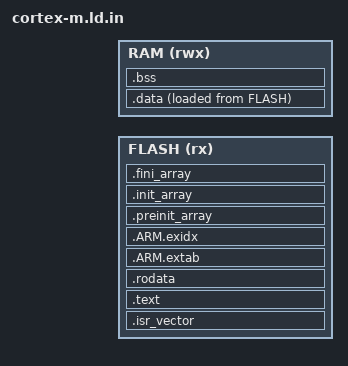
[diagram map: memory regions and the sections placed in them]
/*
 * VirtuLab CI — generic Cortex-M linker script.
 * @FLASH_ORIGIN@ etc. are filled in from the board definition.
 */
ENTRY(Reset_Handler)

MEMORY
{
    FLASH (rx)  : ORIGIN = @FLASH_ORIGIN@, LENGTH = @FLASH_SIZE@
    RAM   (rwx) : ORIGIN = @RAM_ORIGIN@, LENGTH = @RAM_SIZE@
}

_estack = ORIGIN(RAM) + LENGTH(RAM);
_min_stack_size = @MIN_STACK@;

SECTIONS
{
    .isr_vector :
    {
        . = ALIGN(4);
        KEEP(*(.isr_vector))
        KEEP(*(.vectors))
        . = ALIGN(4);
    } > FLASH

    .text :
    {
        *(.text*)
        *(.glue_7)
        *(.glue_7t)
        *(.eh_frame)
        KEEP(*(.init))
        KEEP(*(.fini))
        . = ALIGN(4);
    } > FLASH

    .rodata :
    {
        . = ALIGN(4);
        *(.rodata*)
        . = ALIGN(4);
    } > FLASH

    .ARM.extab : { *(.ARM.extab* .gnu.linkonce.armextab.*) } > FLASH
    .ARM.exidx :
    {
        __exidx_start = .;
        *(.ARM.exidx* .gnu.linkonce.armexidx.*)
        __exidx_end = .;
    } > FLASH

    .preinit_array :
    {
        PROVIDE_HIDDEN(__preinit_array_start = .);
        KEEP(*(.preinit_array*))
        PROVIDE_HIDDEN(__preinit_array_end = .);
    } > FLASH

    .init_array :
    {
        PROVIDE_HIDDEN(__init_array_start = .);
        KEEP(*(SORT(.init_array.*)))
        KEEP(*(.init_array*))
        PROVIDE_HIDDEN(__init_array_end = .);
    } > FLASH

    .fini_array :
    {
        PROVIDE_HIDDEN(__fini_array_start = .);
        KEEP(*(SORT(.fini_array.*)))
        KEEP(*(.fini_array*))
        PROVIDE_HIDDEN(__fini_array_end = .);
    } > FLASH

    _sidata = LOADADDR(.data);

    .data :
    {
        . = ALIGN(4);
        _sdata = .;
        *(.data*)
        . = ALIGN(4);
        _edata = .;
    } > RAM AT > FLASH

    .bss (NOLOAD) :
    {
        . = ALIGN(4);
        _sbss = .;
        __bss_start__ = .;
        *(.bss*)
        *(COMMON)
        . = ALIGN(4);
        _ebss = .;
        __bss_end__ = .;
    } > RAM

    /* newlib's _sbrk grows the heap upward from `end` towards the stack. */
    PROVIDE(end = _ebss);
    PROVIDE(_end = _ebss);

    ASSERT(_ebss + _min_stack_size <= _estack,
           "region `RAM' overflowed: not enough room left for the stack")
}
